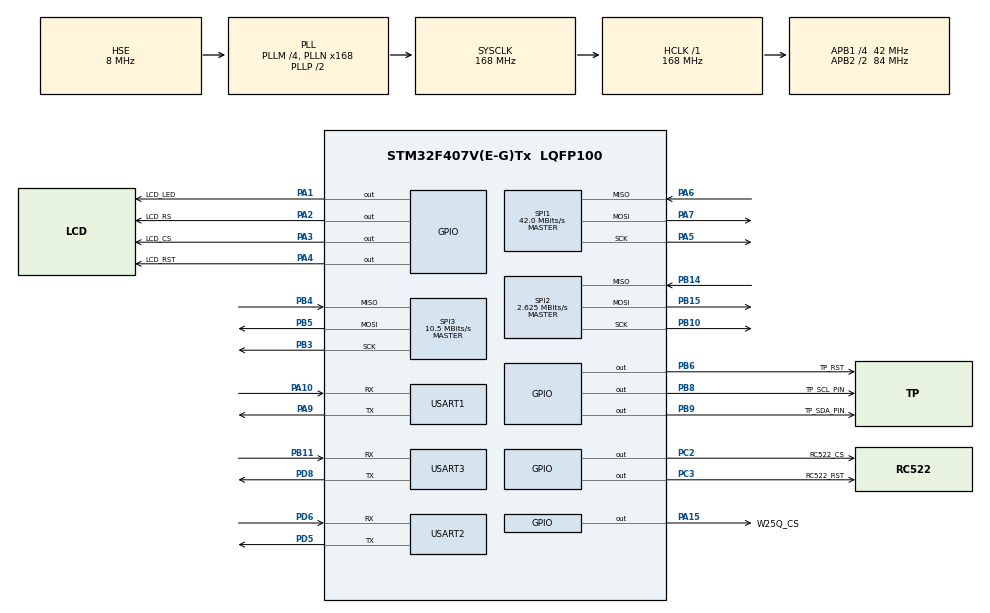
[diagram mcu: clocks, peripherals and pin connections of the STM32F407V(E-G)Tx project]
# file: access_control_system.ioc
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Dma.Request0=USART1_RX
Dma.Request1=SPI1_TX
Dma.Request2=USART3_RX
Dma.SPI1_TX.1.Direction=DMA_MEMORY_TO_PERIPH
Dma.SPI1_TX.1.FIFOMode=DMA_FIFOMODE_DISABLE
Dma.SPI1_TX.1.Instance=DMA2_Stream3
Dma.SPI1_TX.1.MemDataAlignment=DMA_MDATAALIGN_BYTE
Dma.SPI1_TX.1.MemInc=DMA_MINC_ENABLE
Dma.SPI1_TX.1.Mode=DMA_NORMAL
Dma.SPI1_TX.1.PeriphDataAlignment=DMA_PDATAALIGN_BYTE
Dma.SPI1_TX.1.PeriphInc=DMA_PINC_DISABLE
Dma.SPI1_TX.1.Priority=DMA_PRIORITY_LOW
Dma.USART1_RX.0.Direction=DMA_PERIPH_TO_MEMORY
Dma.USART1_RX.0.FIFOMode=DMA_FIFOMODE_DISABLE
Dma.USART1_RX.0.Instance=DMA2_Stream2
Dma.USART1_RX.0.MemDataAlignment=DMA_MDATAALIGN_BYTE
Dma.USART1_RX.0.MemInc=DMA_MINC_ENABLE
Dma.USART1_RX.0.Mode=DMA_NORMAL
Dma.USART1_RX.0.PeriphDataAlignment=DMA_PDATAALIGN_BYTE
Dma.USART1_RX.0.PeriphInc=DMA_PINC_DISABLE
Dma.USART1_RX.0.Priority=DMA_PRIORITY_LOW
Dma.USART3_RX.2.Direction=DMA_PERIPH_TO_MEMORY
Dma.USART3_RX.2.FIFOMode=DMA_FIFOMODE_DISABLE
Dma.USART3_RX.2.Instance=DMA1_Stream1
Dma.USART3_RX.2.MemDataAlignment=DMA_MDATAALIGN_BYTE
Dma.USART3_RX.2.MemInc=DMA_MINC_ENABLE
Dma.USART3_RX.2.Mode=DMA_NORMAL
Dma.USART3_RX.2.PeriphDataAlignment=DMA_PDATAALIGN_BYTE
Dma.USART3_RX.2.PeriphInc=DMA_PINC_DISABLE
Dma.USART3_RX.2.Priority=DMA_PRIORITY_LOW
FREERTOS.Tasks01=defaultTask,24,128,StartDefaultTask,Default,NULL,Dynamic,NULL,NULL
IWDG.Prescaler=IWDG_PRESCALER_256
IWDG.Reload=1000
Mcu.Family=STM32F4
Mcu.Name=STM32F407V(E-G)Tx
Mcu.Package=LQFP100
NVIC.DMA1_Stream1_IRQn=true\:5\:0\:false\:false\:true\:true\:false\:true\:true
NVIC.DMA2_Stream2_IRQn=true\:5\:0\:false\:false\:true\:true\:false\:true\:true
NVIC.DMA2_Stream3_IRQn=true\:5\:0\:false\:false\:true\:true\:false\:true\:true
NVIC.PriorityGroup=NVIC_PRIORITYGROUP_4
NVIC.TIM4_IRQn=true\:15\:0\:false\:false\:true\:false\:false\:true\:true
NVIC.TIM6_DAC_IRQn=true\:5\:0\:false\:false\:true\:true\:true\:true\:true
NVIC.TIM7_IRQn=true\:5\:0\:false\:false\:true\:true\:true\:true\:true
NVIC.TimeBase=TIM4_IRQn
NVIC.TimeBaseIP=TIM4
NVIC.USART1_IRQn=true\:5\:0\:false\:false\:true\:true\:true\:true\:true
NVIC.USART3_IRQn=true\:5\:0\:false\:false\:true\:true\:true\:true\:true
PA1.GPIO_Label=LCD_LED
PA1.GPIO_Speed=GPIO_SPEED_FREQ_HIGH
PA1.PinState=GPIO_PIN_SET
PA1.Signal=GPIO_Output
PA10.Mode=Asynchronous
PA10.Signal=USART1_RX
PA13.Mode=Serial_Wire
PA13.Signal=SYS_JTMS-SWDIO
PA14.Mode=Serial_Wire
PA14.Signal=SYS_JTCK-SWCLK
PA15.GPIO_Label=W25Q_CS
PA15.GPIO_Speed=GPIO_SPEED_FREQ_HIGH
PA15.PinState=GPIO_PIN_SET
PA15.Signal=GPIO_Output
PA2.GPIO_Label=LCD_RS
PA2.GPIO_Speed=GPIO_SPEED_FREQ_HIGH
PA2.PinState=GPIO_PIN_SET
PA2.Signal=GPIO_Output
PA3.GPIO_Label=LCD_CS
PA3.GPIO_PuPd=GPIO_PULLUP
PA3.GPIO_Speed=GPIO_SPEED_FREQ_HIGH
PA3.PinState=GPIO_PIN_SET
PA3.Signal=GPIO_Output
PA4.GPIO_Label=LCD_RST
PA4.GPIO_PuPd=GPIO_PULLUP
PA4.GPIO_Speed=GPIO_SPEED_FREQ_HIGH
PA4.PinState=GPIO_PIN_SET
PA4.Signal=GPIO_Output
PA5.Mode=Full_Duplex_Master
PA5.Signal=SPI1_SCK
PA6.Mode=Full_Duplex_Master
PA6.Signal=SPI1_MISO
PA7.Mode=Full_Duplex_Master
PA7.Signal=SPI1_MOSI
PA9.Mode=Asynchronous
PA9.Signal=USART1_TX
PB10.Mode=Full_Duplex_Master
PB10.Signal=SPI2_SCK
PB11.Mode=Asynchronous
PB11.Signal=USART3_RX
PB14.Mode=Full_Duplex_Master
PB14.Signal=SPI2_MISO
PB15.Mode=Full_Duplex_Master
PB15.Signal=SPI2_MOSI
PB3.Mode=Full_Duplex_Master
PB3.Signal=SPI3_SCK
PB4.Mode=Full_Duplex_Master
PB4.Signal=SPI3_MISO
PB5.Mode=Full_Duplex_Master
PB5.Signal=SPI3_MOSI
PB6.GPIO_Label=TP_RST
PB6.GPIO_Speed=GPIO_SPEED_FREQ_HIGH
PB6.PinState=GPIO_PIN_SET
PB6.Signal=GPIO_Output
PB8.GPIO_Label=TP_SCL_PIN
PB8.GPIO_ModeDefaultOutputPP=GPIO_MODE_OUTPUT_OD
PB8.GPIO_PuPd=GPIO_PULLUP
PB8.GPIO_Speed=GPIO_SPEED_FREQ_HIGH
PB8.PinState=GPIO_PIN_SET
PB8.Signal=GPIO_Output
PB9.GPIO_Label=TP_SDA_PIN
PB9.GPIO_ModeDefaultOutputPP=GPIO_MODE_OUTPUT_OD
PB9.GPIO_PuPd=GPIO_PULLUP
PB9.GPIO_Speed=GPIO_SPEED_FREQ_HIGH
PB9.PinState=GPIO_PIN_SET
PB9.Signal=GPIO_Output
PC2.GPIO_Label=RC522_CS
PC2.GPIO_Speed=GPIO_SPEED_FREQ_HIGH
PC2.PinState=GPIO_PIN_SET
PC2.Signal=GPIO_Output
PC3.GPIO_Label=RC522_RST
PC3.GPIO_Speed=GPIO_SPEED_FREQ_HIGH
PC3.PinState=GPIO_PIN_SET
PC3.Signal=GPIO_Output
PD5.Mode=Asynchronous
PD5.Signal=USART2_TX
PD6.Mode=Asynchronous
PD6.Signal=USART2_RX
PD8.Mode=Asynchronous
PD8.Signal=USART3_TX
PH0-OSC_IN.Mode=HSE-External-Oscillator
PH0-OSC_IN.Signal=RCC_OSC_IN
PH1-OSC_OUT.Mode=HSE-External-Oscillator
PH1-OSC_OUT.Signal=RCC_OSC_OUT
ProjectManager.HeapSize=0x4000
ProjectManager.StackSize=0x1000
ProjectManager.TargetToolchain=MDK-ARM V5.32
RCC.48MHZClocksFreq_Value=84000000
RCC.AHBFreq_Value=168000000
RCC.APB1CLKDivider=RCC_HCLK_DIV4
RCC.APB1Freq_Value=42000000
RCC.APB1TimFreq_Value=84000000
RCC.APB2CLKDivider=RCC_HCLK_DIV2
RCC.APB2Freq_Value=84000000
RCC.APB2TimFreq_Value=168000000
RCC.CortexFreq_Value=168000000
RCC.HCLKFreq_Value=168000000
RCC.HSE_VALUE=8000000
RCC.HSI_VALUE=16000000
RCC.LSE_VALUE=32768
RCC.PLLM=4
RCC.PLLN=168
RCC.PLLSourceVirtual=RCC_PLLSOURCE_HSE
RCC.SYSCLKFreq_VALUE=168000000
RCC.SYSCLKSource=RCC_SYSCLKSOURCE_PLLCLK
RCC.VCOOutputFreq_Value=336000000
SPI1.CLKPhase=SPI_PHASE_2EDGE
SPI1.CLKPolarity=SPI_POLARITY_HIGH
SPI1.CalculateBaudRate=42.0 MBits/s
SPI1.Direction=SPI_DIRECTION_2LINES
SPI1.Mode=SPI_MODE_MASTER
SPI1.VirtualType=VM_MASTER
SPI2.BaudRatePrescaler=SPI_BAUDRATEPRESCALER_16
SPI2.CLKPhase=SPI_PHASE_2EDGE
SPI2.CLKPolarity=SPI_POLARITY_HIGH
SPI2.CalculateBaudRate=2.625 MBits/s
SPI2.Direction=SPI_DIRECTION_2LINES
SPI2.Mode=SPI_MODE_MASTER
SPI2.VirtualType=VM_MASTER
SPI3.BaudRatePrescaler=SPI_BAUDRATEPRESCALER_4
SPI3.CLKPhase=SPI_PHASE_2EDGE
SPI3.CLKPolarity=SPI_POLARITY_HIGH
SPI3.CalculateBaudRate=10.5 MBits/s
SPI3.Direction=SPI_DIRECTION_2LINES
SPI3.Mode=SPI_MODE_MASTER
SPI3.VirtualType=VM_MASTER
TIM6.Period=9
TIM6.Prescaler=8399
TIM7.Period=99
TIM7.Prescaler=8399
USART1.VirtualMode=VM_ASYNC
USART2.VirtualMode=VM_ASYNC
USART3.VirtualMode=VM_ASYNC
VP_FREERTOS_VS_CMSIS_V2.Mode=CMSIS_V2
VP_IWDG_VS_IWDG.Mode=IWDG_Activate
VP_SYS_VS_tim4.Mode=TIM4
VP_TIM6_VS_ClockSourceINT.Mode=Enable_Timer
VP_TIM7_VS_ClockSourceINT.Mode=Enable_Timer
board=custom

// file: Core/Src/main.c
/* USER CODE BEGIN Header */
/**
  ******************************************************************************
  * @file           : main.c
  * @brief          : Main program body
  ******************************************************************************
  * @attention
  *
  * Copyright (c) 2025 STMicroelectronics.
  * All rights reserved.
  *
  * This software is licensed under terms that can be found in the LICENSE file
  * in the root directory of this software component.
  * If no LICENSE file comes with this software, it is provided AS-IS.
  *
  ******************************************************************************
  */
/* USER CODE END Header */
#include "main.h"
#include "cmsis_os.h"
#include "dma.h"
#include "iwdg.h"
#include "spi.h"
#include "tim.h"
#include "usart.h"
#include "gpio.h"

/* USER CODE BEGIN Includes */
#include "app_main.h"
#include "lvgl.h"
/* USER CODE END Includes */

void SystemClock_Config(void);
void MX_FREERTOS_Init(void);

int main(void)
{

  /* USER CODE BEGIN 1 */
	SCB->VTOR = 0x08020000;
  /* USER CODE END 1 */

  /* MCU Configuration--------------------------------------------------------*/

  /* Reset of all peripherals, Initializes the Flash interface and the Systick. */
  HAL_Init();

  /* Configure the system clock */
  SystemClock_Config();

  /* Initialize all configured peripherals */
  MX_GPIO_Init();
  MX_DMA_Init();
  MX_TIM6_Init();
  MX_TIM7_Init();
  MX_SPI3_Init();
  MX_USART1_UART_Init();
  MX_USART2_UART_Init();
  MX_SPI1_Init();
  MX_SPI2_Init();
  MX_USART3_UART_Init();
  MX_IWDG_Init();

  /* Init scheduler */
  osKernelInitialize();

  /* Call init function for freertos objects (in cmsis_os2.c) */
  MX_FREERTOS_Init();

  /* Start scheduler */
  osKernelStart();

  /* We should never get here as control is now taken by the scheduler */

  /* Infinite loop */
  while (1)
  {

  }
}

void SystemClock_Config(void)
{
  RCC_OscInitTypeDef RCC_OscInitStruct = {0};
  RCC_ClkInitTypeDef RCC_ClkInitStruct = {0};

  /** Configure the main internal regulator output voltage
  */
  __HAL_RCC_PWR_CLK_ENABLE();
  __HAL_PWR_VOLTAGESCALING_CONFIG(PWR_REGULATOR_VOLTAGE_SCALE1);

  /** Initializes the RCC Oscillators according to the specified parameters
  * in the RCC_OscInitTypeDef structure.
  */
  RCC_OscInitStruct.OscillatorType = RCC_OSCILLATORTYPE_LSI|RCC_OSCILLATORTYPE_HSE;
  RCC_OscInitStruct.HSEState = RCC_HSE_ON;
  RCC_OscInitStruct.LSIState = RCC_LSI_ON;
  RCC_OscInitStruct.PLL.PLLState = RCC_PLL_ON;
  RCC_OscInitStruct.PLL.PLLSource = RCC_PLLSOURCE_HSE;
  RCC_OscInitStruct.PLL.PLLM = 4;
  RCC_OscInitStruct.PLL.PLLN = 168;
  RCC_OscInitStruct.PLL.PLLP = RCC_PLLP_DIV2;
  RCC_OscInitStruct.PLL.PLLQ = 4;
  if (HAL_RCC_OscConfig(&RCC_OscInitStruct) != HAL_OK)
  {
    Error_Handler();
  }

  /** Initializes the CPU, AHB and APB buses clocks
  */
  RCC_ClkInitStruct.ClockType = RCC_CLOCKTYPE_HCLK|RCC_CLOCKTYPE_SYSCLK
                              |RCC_CLOCKTYPE_PCLK1|RCC_CLOCKTYPE_PCLK2;
  RCC_ClkInitStruct.SYSCLKSource = RCC_SYSCLKSOURCE_PLLCLK;
  RCC_ClkInitStruct.AHBCLKDivider = RCC_SYSCLK_DIV1;
  RCC_ClkInitStruct.APB1CLKDivider = RCC_HCLK_DIV4;
  RCC_ClkInitStruct.APB2CLKDivider = RCC_HCLK_DIV2;

  if (HAL_RCC_ClockConfig(&RCC_ClkInitStruct, FLASH_LATENCY_5) != HAL_OK)
  {
    Error_Handler();
  }
}

void HAL_TIM_PeriodElapsedCallback(TIM_HandleTypeDef *htim)
{
  if (htim->Instance == TIM4) {
    HAL_IncTick();
  }
  /* USER CODE BEGIN Callback 1 */
  if(htim->Instance == TIM6){
		lv_tick_inc(1);
	}
  /* USER CODE END Callback 1 */
}

void Error_Handler(void)
{
  __disable_irq();
  while (1)
  {
  }
}
